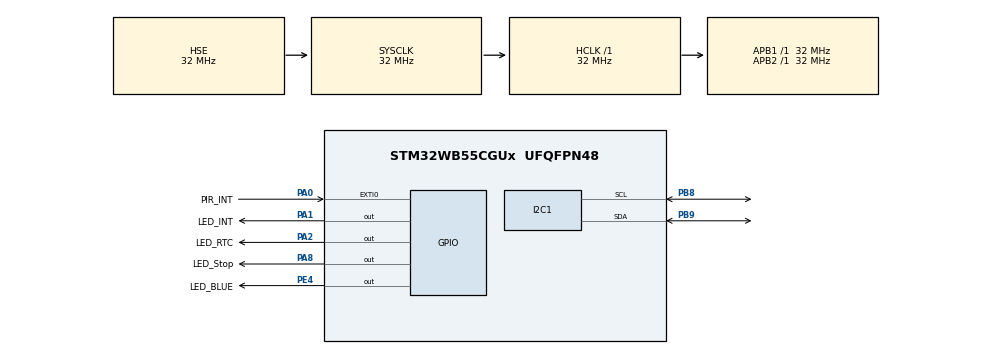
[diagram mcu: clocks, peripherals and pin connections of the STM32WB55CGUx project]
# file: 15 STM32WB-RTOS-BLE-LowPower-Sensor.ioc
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ADC1.Channel-0\#ChannelRegularConversion=ADC_CHANNEL_VBAT
ADC1.NbrOfConversionFlag=1
ADC1.OffsetNumber-0\#ChannelRegularConversion=ADC_OFFSET_NONE
ADC1.Rank-0\#ChannelRegularConversion=1
ADC1.SamplingTime-0\#ChannelRegularConversion=ADC_SAMPLETIME_640CYCLES_5
ADC1.master=1
Dma.I2C1_RX.0.Direction=DMA_PERIPH_TO_MEMORY
Dma.I2C1_RX.0.EventEnable=DISABLE
Dma.I2C1_RX.0.Instance=DMA1_Channel3
Dma.I2C1_RX.0.MemDataAlignment=DMA_MDATAALIGN_BYTE
Dma.I2C1_RX.0.MemInc=DMA_MINC_ENABLE
Dma.I2C1_RX.0.Mode=DMA_NORMAL
Dma.I2C1_RX.0.PeriphDataAlignment=DMA_PDATAALIGN_BYTE
Dma.I2C1_RX.0.PeriphInc=DMA_PINC_DISABLE
Dma.I2C1_RX.0.Polarity=HAL_DMAMUX_REQ_GEN_RISING
Dma.I2C1_RX.0.Priority=DMA_PRIORITY_LOW
Dma.I2C1_RX.0.RequestNumber=1
Dma.I2C1_RX.0.SignalID=NONE
Dma.I2C1_RX.0.SyncEnable=DISABLE
Dma.I2C1_RX.0.SyncPolarity=HAL_DMAMUX_SYNC_NO_EVENT
Dma.I2C1_RX.0.SyncRequestNumber=1
Dma.I2C1_RX.0.SyncSignalID=NONE
Dma.I2C1_TX.1.Direction=DMA_MEMORY_TO_PERIPH
Dma.I2C1_TX.1.EventEnable=DISABLE
Dma.I2C1_TX.1.Instance=DMA1_Channel2
Dma.I2C1_TX.1.MemDataAlignment=DMA_MDATAALIGN_BYTE
Dma.I2C1_TX.1.MemInc=DMA_MINC_ENABLE
Dma.I2C1_TX.1.Mode=DMA_NORMAL
Dma.I2C1_TX.1.PeriphDataAlignment=DMA_PDATAALIGN_BYTE
Dma.I2C1_TX.1.PeriphInc=DMA_PINC_DISABLE
Dma.I2C1_TX.1.Polarity=HAL_DMAMUX_REQ_GEN_RISING
Dma.I2C1_TX.1.Priority=DMA_PRIORITY_LOW
Dma.I2C1_TX.1.RequestNumber=1
Dma.I2C1_TX.1.SignalID=NONE
Dma.I2C1_TX.1.SyncEnable=DISABLE
Dma.I2C1_TX.1.SyncPolarity=HAL_DMAMUX_SYNC_NO_EVENT
Dma.I2C1_TX.1.SyncRequestNumber=1
Dma.I2C1_TX.1.SyncSignalID=NONE
Dma.Request0=I2C1_RX
Dma.Request1=I2C1_TX
FREERTOS.Queues01=xSensorToBleQueue,4,32,1,Dynamic,NULL,NULL;xBLECmdQueue,8,24,1,Dynamic,NULL,NULL
FREERTOS.Tasks01=SensorTask,24,512,StartSensorTask,Default,NULL,Dynamic,NULL,NULL;BLETask,32,1024,StartBLETask,Default,NULL,Dynamic,NULL,NULL;PowerTask,40,256,StartPowerTask,Default,NULL,Dynamic,NULL,NULL;OTATask,16,1024,StartOTATask,Default,NULL,Dynamic,NULL,NULL
FREERTOS.configCHECK_FOR_STACK_OVERFLOW=2
FREERTOS.configTOTAL_HEAP_SIZE=12288
FREERTOS.configUSE_IDLE_HOOK=1
FREERTOS.configUSE_MALLOC_FAILED_HOOK=1
FREERTOS.configUSE_TICKLESS_IDLE=0
I2C1.Timing=0x00B07CB4
Mcu.Family=STM32WB
Mcu.Name=STM32WB55CGUx
Mcu.Package=UFQFPN48
NVIC.DMA1_Channel2_IRQn=true\:5\:0\:false\:false\:true\:true\:false\:true\:true
NVIC.DMA1_Channel3_IRQn=true\:5\:0\:false\:false\:true\:true\:false\:true\:true
NVIC.EXTI0_IRQn=true\:5\:0\:false\:false\:true\:true\:true\:true\:true
NVIC.HSEM_IRQn=true\:5\:0\:false\:false\:true\:true\:false\:true\:true
NVIC.I2C1_ER_IRQn=true\:5\:0\:true\:false\:true\:true\:true\:true\:true
NVIC.I2C1_EV_IRQn=true\:5\:0\:true\:false\:true\:true\:true\:true\:true
NVIC.IPCC_C1_RX_IRQn=true\:5\:0\:false\:false\:true\:true\:true\:true\:true
NVIC.IPCC_C1_TX_IRQn=true\:5\:0\:false\:false\:true\:true\:true\:true\:true
NVIC.PriorityGroup=NVIC_PRIORITYGROUP_4
NVIC.TIM1_UP_TIM16_IRQn=true\:15\:0\:false\:false\:true\:false\:false\:true\:true
NVIC.TimeBase=TIM1_UP_TIM16_IRQn
NVIC.TimeBaseIP=TIM1
OSC_IN.Mode=HSE-External-Oscillator
OSC_IN.Signal=RCC_OSC_IN
OSC_OUT.Mode=HSE-External-Oscillator
OSC_OUT.Signal=RCC_OSC_OUT
PA0.GPIO_Label=PIR_INT
PA0.Signal=GPXTI0
PA1.GPIO_Label=LED_INT
PA1.Signal=GPIO_Output
PA13.Mode=Serial_Wire
PA13.Signal=SYS_JTMS-SWDIO
PA14.Mode=Serial_Wire
PA14.Signal=SYS_JTCK-SWCLK
PA2.GPIO_Label=LED_RTC
PA2.Signal=GPIO_Output
PA8.GPIO_Label=LED_Stop
PA8.Signal=GPIO_Output
PB8.Mode=I2C
PB8.Signal=I2C1_SCL
PB9.Mode=I2C
PB9.Signal=I2C1_SDA
PC14-OSC32_IN.Mode=LSE-External-Oscillator
PC14-OSC32_IN.Signal=RCC_OSC32_IN
PC15-OSC32_OUT.Mode=LSE-External-Oscillator
PC15-OSC32_OUT.Signal=RCC_OSC32_OUT
PE4.GPIO_Label=LED_BLUE
PE4.Signal=GPIO_Output
ProjectManager.HeapSize=0x200
ProjectManager.StackSize=0x400
ProjectManager.TargetToolchain=STM32CubeIDE
RCC.ADCFreq_Value=64000000
RCC.AHBFreq_Value=32000000
RCC.APB1Freq_Value=32000000
RCC.APB1TimFreq_Value=32000000
RCC.APB2Freq_Value=32000000
RCC.APB2TimFreq_Value=32000000
RCC.APB3Freq_Value=16000000
RCC.CortexFreq_Value=32000000
RCC.HCLKFreq_Value=32000000
RCC.HSE_VALUE=32000000
RCC.HSI48_VALUE=48000000
RCC.HSI_VALUE=16000000
RCC.MSIClockRange=RCC_MSIRANGE_8
RCC.PLLR=RCC_PLLR_DIV4
RCC.RFWKPClockSelection=RCC_RFWKPCLKSOURCE_LSE
RCC.RTCClockSelection=RCC_RTCCLKSOURCE_LSE
RCC.SYSCLKFreq_VALUE=32000000
RCC.SYSCLKSource=RCC_SYSCLKSOURCE_HSE
RCC.USBFreq_Value=64000000
RCC.VCOOutputFreq_Value=128000000
RF1.Mode=RF1_Activate
RF1.Signal=RF_RF1
STM32_WPAN.CFG_BLE_NUM_GATT_ATTRIBUTES=88
STM32_WPAN.CFG_DEBUGGER_SUPPORTED=0
STM32_WPAN.CFG_LPM_SUPPORTED=1
STM32_WPAN.CFG_LSCLK_LSE=0
VP_ADC1_Vbat_Input.Mode=IN-Vbat
VP_FREERTOS_VS_CMSIS_V2.Mode=CMSIS_V2
VP_HSEM_VS_HSEM.Mode=HSEM_Activate
VP_IPCC_VS_IPCC.Mode=IPCC_Activate
VP_MEMORYMAP_VS_MEMORYMAP.Mode=CurAppReg
VP_RTC_VS_RTC_Activate.Mode=RTC_Enabled
VP_STM32_WPAN_VS_BLE_HOST.Mode=STM32_WPAN_Enabled
VP_SYS_VS_tim1.Mode=TIM1
VP_TINY_LPM_VS_TINY_LPM.Mode=TINY_LPM_Enabled
board=custom

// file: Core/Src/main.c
/* USER CODE BEGIN Header */
/**
  ******************************************************************************
  * @file           : main.c
  * @brief          : Main program body
  ******************************************************************************
  * @attention
  *
  * Copyright (c) 2026 STMicroelectronics.
  * All rights reserved.
  *
  * This software is licensed under terms that can be found in the LICENSE file
  * in the root directory of this software component.
  * If no LICENSE file comes with this software, it is provided AS-IS.
  *
  ******************************************************************************
  */
/* USER CODE END Header */
#include "main.h"
#include "cmsis_os2.h"
#include "FreeRTOS.h"
#include "adc.h"
#include "dma.h"
#include "i2c.h"
#include "ipcc.h"
#include "rf.h"
#include "rtc.h"
#include "gpio.h"

void SystemClock_Config(void);
void PeriphCommonClock_Config(void);
void MX_FREERTOS_Init(void);

int main(void)
{

  /* MCU Configuration--------------------------------------------------------*/

  /* Reset of all peripherals, Initializes the Flash interface and the Systick. */
  HAL_Init();
  /* Config code for STM32_WPAN (HSE Tuning must be done before system clock configuration) */
  MX_APPE_Config();

  /* Configure the system clock */
  SystemClock_Config();

  /* Configure the peripherals common clocks */
  PeriphCommonClock_Config();

  /* IPCC initialisation */
  MX_IPCC_Init();

  /* Initialize all configured peripherals */
  MX_GPIO_Init();
  MX_DMA_Init();
  MX_RTC_Init();
  MX_I2C1_Init();
  MX_ADC1_Init();
  MX_RF_Init();

  /* Init scheduler */
  osKernelInitialize();
  /* Init code for STM32_WPAN */
  MX_APPE_Init();
  /* Call init function for freertos objects (in cmsis_os2.c) */
  MX_FREERTOS_Init();

  /* Start scheduler */
  osKernelStart();

  /* We should never get here as control is now taken by the scheduler */

  /* Infinite loop */
  while (1)
  {

  }
}

void SystemClock_Config(void)
{
  RCC_OscInitTypeDef RCC_OscInitStruct = {0};
  RCC_ClkInitTypeDef RCC_ClkInitStruct = {0};

  /** Macro to configure the PLL multiplication factor
  */
  __HAL_RCC_PLL_PLLM_CONFIG(RCC_PLLM_DIV1);

  /** Macro to configure the PLL clock source
  */
  __HAL_RCC_PLL_PLLSOURCE_CONFIG(RCC_PLLSOURCE_MSI);

  /** Configure LSE Drive Capability
  */
  HAL_PWR_EnableBkUpAccess();
  __HAL_RCC_LSEDRIVE_CONFIG(RCC_LSEDRIVE_MEDIUMHIGH);

  /** Configure the main internal regulator output voltage
  */
  __HAL_PWR_VOLTAGESCALING_CONFIG(PWR_REGULATOR_VOLTAGE_SCALE1);

  /** Initializes the RCC Oscillators according to the specified parameters
  * in the RCC_OscInitTypeDef structure.
  */
  RCC_OscInitStruct.OscillatorType = RCC_OSCILLATORTYPE_HSI|RCC_OSCILLATORTYPE_HSE
                              |RCC_OSCILLATORTYPE_LSE|RCC_OSCILLATORTYPE_MSI;
  RCC_OscInitStruct.HSEState = RCC_HSE_ON;
  RCC_OscInitStruct.LSEState = RCC_LSE_ON;
  RCC_OscInitStruct.HSIState = RCC_HSI_ON;
  RCC_OscInitStruct.MSIState = RCC_MSI_ON;
  RCC_OscInitStruct.HSICalibrationValue = RCC_HSICALIBRATION_DEFAULT;
  RCC_OscInitStruct.MSICalibrationValue = RCC_MSICALIBRATION_DEFAULT;
  RCC_OscInitStruct.MSIClockRange = RCC_MSIRANGE_8;
  RCC_OscInitStruct.PLL.PLLState = RCC_PLL_NONE;
  if (HAL_RCC_OscConfig(&RCC_OscInitStruct) != HAL_OK)
  {
    Error_Handler();
  }

  /** Configure the SYSCLKSource, HCLK, PCLK1 and PCLK2 clocks dividers
  */
  RCC_ClkInitStruct.ClockType = RCC_CLOCKTYPE_HCLK4|RCC_CLOCKTYPE_HCLK2
                              |RCC_CLOCKTYPE_HCLK|RCC_CLOCKTYPE_SYSCLK
                              |RCC_CLOCKTYPE_PCLK1|RCC_CLOCKTYPE_PCLK2;
  RCC_ClkInitStruct.SYSCLKSource = RCC_SYSCLKSOURCE_HSE;
  RCC_ClkInitStruct.AHBCLKDivider = RCC_SYSCLK_DIV1;
  RCC_ClkInitStruct.APB1CLKDivider = RCC_HCLK_DIV1;
  RCC_ClkInitStruct.APB2CLKDivider = RCC_HCLK_DIV1;
  RCC_ClkInitStruct.AHBCLK2Divider = RCC_SYSCLK_DIV1;
  RCC_ClkInitStruct.AHBCLK4Divider = RCC_SYSCLK_DIV1;

  if (HAL_RCC_ClockConfig(&RCC_ClkInitStruct, FLASH_LATENCY_1) != HAL_OK)
  {
    Error_Handler();
  }
}

void PeriphCommonClock_Config(void)
{
  RCC_PeriphCLKInitTypeDef PeriphClkInitStruct = {0};

  /** Initializes the peripherals clock
  */
  PeriphClkInitStruct.PeriphClockSelection = RCC_PERIPHCLK_SMPS|RCC_PERIPHCLK_RFWAKEUP;
  PeriphClkInitStruct.RFWakeUpClockSelection = RCC_RFWKPCLKSOURCE_LSE;
  PeriphClkInitStruct.SmpsClockSelection = RCC_SMPSCLKSOURCE_HSI;
  PeriphClkInitStruct.SmpsDivSelection = RCC_SMPSCLKDIV_RANGE1;

  if (HAL_RCCEx_PeriphCLKConfig(&PeriphClkInitStruct) != HAL_OK)
  {
    Error_Handler();
  }
}

void HAL_TIM_PeriodElapsedCallback(TIM_HandleTypeDef *htim)
{
  if (htim->Instance == TIM1)
  {
    HAL_IncTick();
  }
}

void Error_Handler(void)
{
  __disable_irq();
  while (1)
  {
  }
}

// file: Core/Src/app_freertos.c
/* USER CODE BEGIN Header */
/**
  ******************************************************************************
  * File Name          : app_freertos.c
  * Description        : Code for freertos applications
  ******************************************************************************
  * @attention
  *
  * Copyright (c) 2026 STMicroelectronics.
  * All rights reserved.
  *
  * This software is licensed under terms that can be found in the LICENSE file
  * in the root directory of this software component.
  * If no LICENSE file comes with this software, it is provided AS-IS.
  *
  ******************************************************************************
  */
/* USER CODE END Header */

#include "FreeRTOS.h"
#include "task.h"
#include "main.h"
#include "cmsis_os2.h"
#include "FreeRTOS.h"

/* USER CODE BEGIN Includes */
#include "ble_task.h"
#include "power_manager.h"
#include "ota_task.h"
#include "sensor_task.h"
#include "stm32_lpm.h"
/* USER CODE END Includes */

/* Definitions for SensorTask */
osThreadId_t SensorTaskHandle;
const osThreadAttr_t SensorTask_attributes = {
  .name = "SensorTask",
  .priority = (osPriority_t) osPriorityNormal,
  .stack_size = 512 * 4
};
/* Definitions for BLETask */
osThreadId_t BLETaskHandle;
const osThreadAttr_t BLETask_attributes = {
  .name = "BLETask",
  .priority = (osPriority_t) osPriorityAboveNormal,
  .stack_size = 1024 * 4
};
/* Definitions for PowerTask */
osThreadId_t PowerTaskHandle;
const osThreadAttr_t PowerTask_attributes = {
  .name = "PowerTask",
  .priority = (osPriority_t) osPriorityHigh,
  .stack_size = 256 * 4
};
/* Definitions for OTATask */
osThreadId_t OTATaskHandle;
const osThreadAttr_t OTATask_attributes = {
  .name = "OTATask",
  .priority = (osPriority_t) osPriorityBelowNormal,
  .stack_size = 1024 * 4
};
/* Definitions for xSensorToBleQueue */
osMessageQueueId_t xSensorToBleQueueHandle;
const osMessageQueueAttr_t xSensorToBleQueue_attributes = {
  .name = "xSensorToBleQueue"
};
/* Definitions for xBLECmdQueue */
osMessageQueueId_t xBLECmdQueueHandle;
const osMessageQueueAttr_t xBLECmdQueue_attributes = {
  .name = "xBLECmdQueue"
};

void StartSensorTask(void *argument);
void StartBLETask(void *argument);
void StartPowerTask(void *argument);
void StartOTATask(void *argument);

void MX_FREERTOS_Init(void); /* (MISRA C 2004 rule 8.1) */

/* Hook prototypes */
void vApplicationIdleHook(void);
void vApplicationStackOverflowHook(TaskHandle_t xTask, char *pcTaskName);
void vApplicationMallocFailedHook(void);

/* USER CODE BEGIN 2 */
void vApplicationIdleHook( void )
{
   /* vApplicationIdleHook() will only be called if configUSE_IDLE_HOOK is set
   to 1 in FreeRTOSConfig.h. It will be called on each iteration of the idle
   task. It is essential that code added to this hook function never attempts
   to block in any way (for example, call xQueueReceive() with a block time
   specified, or call vTaskDelay()). If the application makes use of the
   vTaskDelete() API function (as this demo application does) then it is also
   important that vApplicationIdleHook() is permitted to return to its calling
   function, because it is the responsibility of the idle task to clean up
   memory allocated by the kernel to any task that has since been deleted. */
	HAL_GPIO_WritePin(GPIOA, LED_Stop_Pin, GPIO_PIN_SET);
	UTIL_LPM_EnterLowPower();
}
/* USER CODE END 2 */

/* USER CODE BEGIN 4 */
void vApplicationStackOverflowHook(TaskHandle_t xTask, char *pcTaskName)
{
   /* Run time stack overflow checking is performed if
   configCHECK_FOR_STACK_OVERFLOW is defined to 1 or 2. This hook function is
   called if a stack overflow is detected. */
}
/* USER CODE END 4 */

/* USER CODE BEGIN 5 */
void vApplicationMallocFailedHook(void)
{
   /* vApplicationMallocFailedHook() will only be called if
   configUSE_MALLOC_FAILED_HOOK is set to 1 in FreeRTOSConfig.h. It is a hook
   function that will get called if a call to pvPortMalloc() fails.
   pvPortMalloc() is called internally by the kernel whenever a task, queue,
   timer or semaphore is created. It is also called by various parts of the
   demo application. If heap_1.c or heap_2.c are used, then the size of the
   heap available to pvPortMalloc() is defined by configTOTAL_HEAP_SIZE in
   FreeRTOSConfig.h, and the xPortGetFreeHeapSize() API function can be used
   to query the size of free heap space that remains (although it does not
   provide information on how the remaining heap might be fragmented). */
}
/* USER CODE END 5 */

void MX_FREERTOS_Init(void) {

  /* Create the queue(s) */
  /* creation of xSensorToBleQueue */
  xSensorToBleQueueHandle = osMessageQueueNew (4, 32, &xSensorToBleQueue_attributes);

  /* creation of xBLECmdQueue */
  xBLECmdQueueHandle = osMessageQueueNew (8, 24, &xBLECmdQueue_attributes);

  /* Create the thread(s) */
  /* creation of SensorTask */
  SensorTaskHandle = osThreadNew(StartSensorTask, NULL, &SensorTask_attributes);

  /* creation of BLETask */
  BLETaskHandle = osThreadNew(StartBLETask, NULL, &BLETask_attributes);

  /* creation of PowerTask */
  PowerTaskHandle = osThreadNew(StartPowerTask, NULL, &PowerTask_attributes);

  /* creation of OTATask */
  OTATaskHandle = osThreadNew(StartOTATask, NULL, &OTATask_attributes);

}

void StartSensorTask(void *argument)
{
  /* USER CODE BEGIN StartSensorTask */
	SensorTask_Run(argument);
  /* USER CODE END StartSensorTask */
}

void StartBLETask(void *argument)
{
  /* USER CODE BEGIN StartBLETask */
	BLETask_Run(argument);
  /* USER CODE END StartBLETask */
}

void StartPowerTask(void *argument)
{
  /* USER CODE BEGIN StartPowerTask */
	PowerTask_Run(argument);
  /* USER CODE END StartPowerTask */
}

void StartOTATask(void *argument)
{
  /* USER CODE BEGIN StartOTATask */
	OTATask_Run(argument);
  /* USER CODE END StartOTATask */
}
